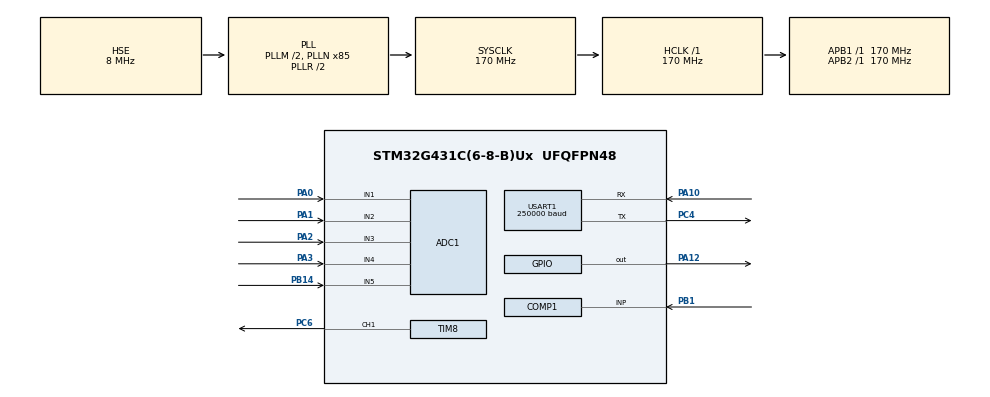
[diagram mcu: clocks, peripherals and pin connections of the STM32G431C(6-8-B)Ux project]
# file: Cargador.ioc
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ADC1.Channel-0\#ChannelRegularConversion=ADC_CHANNEL_1
ADC1.Channel-1\#ChannelRegularConversion=ADC_CHANNEL_3
ADC1.Channel-2\#ChannelRegularConversion=ADC_CHANNEL_5
ADC1.ClockPrescaler=ADC_CLOCK_ASYNC_DIV6
ADC1.DMAContinuousRequests=ENABLE
ADC1.ExternalTrigConv=ADC_EXTERNALTRIG_T6_TRGO
ADC1.ExternalTrigConvEdge=ADC_EXTERNALTRIGCONVEDGE_RISING
ADC1.NbrOfConversion=3
ADC1.NbrOfConversionFlag=1
ADC1.OffsetNumber-0\#ChannelRegularConversion=ADC_OFFSET_NONE
ADC1.OffsetNumber-1\#ChannelRegularConversion=ADC_OFFSET_NONE
ADC1.OffsetNumber-2\#ChannelRegularConversion=ADC_OFFSET_NONE
ADC1.Rank-0\#ChannelRegularConversion=1
ADC1.Rank-1\#ChannelRegularConversion=2
ADC1.Rank-2\#ChannelRegularConversion=3
ADC1.SamplingTime-0\#ChannelRegularConversion=ADC_SAMPLETIME_47CYCLES_5
ADC1.SamplingTime-1\#ChannelRegularConversion=ADC_SAMPLETIME_47CYCLES_5
ADC1.SamplingTime-2\#ChannelRegularConversion=ADC_SAMPLETIME_24CYCLES_5
ADC1.SingleDiff-0\#ChannelRegularConversion=ADC_DIFFERENTIAL_ENDED
ADC1.SingleDiff-1\#ChannelRegularConversion=ADC_DIFFERENTIAL_ENDED
ADC1.master=1
CRC.DefaultPolynomialUse=DEFAULT_POLYNOMIAL_ENABLE
CRC.InputDataFormat=CRC_INPUTDATA_FORMAT_BYTES
Dma.ADC1.0.Direction=DMA_PERIPH_TO_MEMORY
Dma.ADC1.0.EventEnable=DISABLE
Dma.ADC1.0.Instance=DMA1_Channel1
Dma.ADC1.0.MemDataAlignment=DMA_MDATAALIGN_WORD
Dma.ADC1.0.MemInc=DMA_MINC_ENABLE
Dma.ADC1.0.Mode=DMA_CIRCULAR
Dma.ADC1.0.PeriphDataAlignment=DMA_PDATAALIGN_WORD
Dma.ADC1.0.PeriphInc=DMA_PINC_DISABLE
Dma.ADC1.0.Polarity=HAL_DMAMUX_REQ_GEN_RISING
Dma.ADC1.0.Priority=DMA_PRIORITY_VERY_HIGH
Dma.ADC1.0.RequestNumber=1
Dma.ADC1.0.SignalID=NONE
Dma.ADC1.0.SyncEnable=DISABLE
Dma.ADC1.0.SyncPolarity=HAL_DMAMUX_SYNC_NO_EVENT
Dma.ADC1.0.SyncRequestNumber=1
Dma.ADC1.0.SyncSignalID=NONE
Dma.Request0=ADC1
Mcu.Family=STM32G4
Mcu.Name=STM32G431C(6-8-B)Ux
Mcu.Package=UFQFPN48
NVIC.PriorityGroup=NVIC_PRIORITYGROUP_4
NVIC.TIM2_IRQn=true\:15\:0\:false\:false\:true\:false\:true\:true
NVIC.TIM6_DAC_IRQn=true\:0\:0\:true\:false\:true\:true\:true\:true
NVIC.TIM7_IRQn=true\:4\:0\:true\:false\:true\:true\:true\:true
NVIC.TIM8_BRK_IRQn=true\:1\:0\:true\:false\:true\:true\:true\:true
NVIC.TimeBase=TIM2_IRQn
NVIC.TimeBaseIP=TIM2
PA0.Mode=IN1-Differential
PA0.Signal=ADC1_IN1
PA1.Mode=IN1-Differential
PA1.Signal=ADC1_IN2
PA10.Mode=Asynchronous
PA10.Signal=USART1_RX
PA12.PinState=GPIO_PIN_SET
PA12.Signal=GPIO_Output
PA13.Mode=Trace_Asynchronous_SW
PA13.Signal=SYS_JTMS-SWDIO
PA14.Mode=Trace_Asynchronous_SW
PA14.Signal=SYS_JTCK-SWCLK
PA2.Mode=IN3-Differential
PA2.Signal=ADC1_IN3
PA3.Mode=IN3-Differential
PA3.Signal=ADC1_IN4
PB1.Mode=INP
PB1.Signal=COMP1_INP
PB14.Mode=IN5-Single-Ended
PB14.Signal=ADC1_IN5
PB3.Mode=Trace_Asynchronous_SW
PB3.Signal=SYS_JTDO-SWO
PC4.Mode=Asynchronous
PC4.Signal=USART1_TX
PC6.Signal=S_TIM8_CH1
PF0-OSC_IN.Mode=HSE-External-Oscillator
PF0-OSC_IN.Signal=RCC_OSC_IN
PF1-OSC_OUT.Mode=HSE-External-Oscillator
PF1-OSC_OUT.Signal=RCC_OSC_OUT
ProjectManager.HeapSize=0x200
ProjectManager.StackSize=0x400
ProjectManager.TargetToolchain=STM32CubeIDE
RCC.ADC12Freq_Value=170000000
RCC.AHBFreq_Value=170000000
RCC.APB1Freq_Value=170000000
RCC.APB1TimFreq_Value=170000000
RCC.APB2Freq_Value=170000000
RCC.APB2TimFreq_Value=170000000
RCC.CortexFreq_Value=170000000
RCC.EXTERNAL_CLOCK_VALUE=12288000
RCC.HCLKFreq_Value=170000000
RCC.HSE_VALUE=8000000
RCC.HSI48_VALUE=48000000
RCC.HSI_VALUE=16000000
RCC.LSE_VALUE=32768
RCC.PLLM=RCC_PLLM_DIV2
RCC.PLLN=85
RCC.PLLSourceVirtual=RCC_PLLSOURCE_HSE
RCC.SYSCLKFreq_VALUE=170000000
RCC.SYSCLKSource=RCC_SYSCLKSOURCE_PLLCLK
RCC.USBFreq_Value=170000000
RCC.VCOOutputFreq_Value=340000000
SH.S_TIM8_CH1.0=TIM8_CH1,PWM Generation1 CH1
STMicroelectronics.X-CUBE-ALGOBUILD.1.4.0.LibraryCcDSPOoLibraryJjDSPOoLibrary=true
TIM6.AutoReloadPreload=TIM_AUTORELOAD_PRELOAD_ENABLE
TIM6.PeriodNoDither=8500
TIM6.TIM_MasterOutputTrigger=TIM_TRGO_UPDATE
TIM7.PeriodNoDither=17000
TIM7.Prescaler=9
TIM8.AutoReloadPreload=TIM_AUTORELOAD_PRELOAD_DISABLE
TIM8.BreakFilter=5
TIM8.BreakPolarity=TIM_BREAKPOLARITY_LOW
TIM8.BreakState=TIM_BREAK_ENABLE
TIM8.Channel-PWM\ Generation1\ CH1=TIM_CHANNEL_1
TIM8.OCFastMode_PWM-PWM\ Generation1\ CH1=TIM_OCFAST_ENABLE
TIM8.OffStateIDLEMode=TIM_OSSI_ENABLE
TIM8.OffStateRunMode=TIM_OSSR_ENABLE
TIM8.PeriodNoDither=11333
TIM8.PulseNoDither_1=8000
TIM8.SourceBRKCOMP1=TIM_BREAKINPUTSOURCE_ENABLE
TIM8.SourceBRKCOMP1Polarity=TIM_BREAKINPUTSOURCE_POLARITY_LOW
TIM8.TIM_MasterOutputTrigger=TIM_TRGO_UPDATE
USART1.BaudRate=250000
USART1.VirtualMode-Asynchronous=VM_ASYNC
VP_COMP1_VS_DAC1OUT1.Mode=INM_DAC1OUT1
VP_CORDIC_VS_CORDIC.Mode=CORDIC_Activate
VP_CRC_VS_CRC.Mode=CRC_Activate
VP_DAC1_VS_DACI1.Mode=DAC_OUT1_Int
VP_STMicroelectronics.X-CUBE-ALGOBUILD_VS_DSPOoLibraryJjLibrary_1.4.0_1.4.0.Mode=DSPOoLibraryJjLibrary
VP_SYS_VS_DBSignals.Mode=DisableDeadBatterySignals
VP_SYS_VS_tim2.Mode=TIM2
VP_TIM6_VS_ClockSourceINT.Mode=Enable_Timer
VP_TIM7_VS_ClockSourceINT.Mode=Enable_Timer
VP_TIM8_VS_ClockSourceINT.Mode=Internal
board=custom

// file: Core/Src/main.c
/* USER CODE BEGIN Header */
/**
 ******************************************************************************
 * @file           : main.c
 * @brief          : Main program body
 ******************************************************************************
 * @attention
 *
 * Copyright (c) 2025 STMicroelectronics.
 * All rights reserved.
 *
 * This software is licensed under terms that can be found in the LICENSE file
 * in the root directory of this software component.
 * If no LICENSE file comes with this software, it is provided AS-IS.
 *
 ******************************************************************************
 */
/* USER CODE END Header */
#include "main.h"

/* USER CODE BEGIN Includes */
#include "UserMain.h"
/* USER CODE END Includes */

ADC_HandleTypeDef hadc1;
DMA_HandleTypeDef hdma_adc1;

COMP_HandleTypeDef hcomp1;

CORDIC_HandleTypeDef hcordic;

CRC_HandleTypeDef hcrc;

DAC_HandleTypeDef hdac1;

TIM_HandleTypeDef htim6;
TIM_HandleTypeDef htim7;
TIM_HandleTypeDef htim8;

UART_HandleTypeDef huart1;

void SystemClock_Config(void);
static void MX_GPIO_Init(void);
static void MX_DMA_Init(void);
static void MX_ADC1_Init(void);
static void MX_TIM6_Init(void);
static void MX_CORDIC_Init(void);
static void MX_USART1_UART_Init(void);
static void MX_TIM7_Init(void);
static void MX_CRC_Init(void);
static void MX_TIM8_Init(void);
static void MX_DAC1_Init(void);
static void MX_COMP1_Init(void);

int main(void)
{

  /* MCU Configuration--------------------------------------------------------*/

  /* Reset of all peripherals, Initializes the Flash interface and the Systick. */
  HAL_Init();

  /* Configure the system clock */
  SystemClock_Config();

  /* Initialize all configured peripherals */
  MX_GPIO_Init();
  MX_DMA_Init();
  MX_ADC1_Init();
  MX_TIM6_Init();
  MX_CORDIC_Init();
  MX_USART1_UART_Init();
  MX_TIM7_Init();
  MX_CRC_Init();
  MX_TIM8_Init();
  MX_DAC1_Init();
  MX_COMP1_Init();
  /* USER CODE BEGIN 2 */
	setup();

  /* USER CODE END 2 */

  /* Infinite loop */
	while (1) {

    /* USER CODE BEGIN 3 */
		loop();
	}
  /* USER CODE END 3 */
}

void SystemClock_Config(void)
{
  RCC_OscInitTypeDef RCC_OscInitStruct = {0};
  RCC_ClkInitTypeDef RCC_ClkInitStruct = {0};

  /** Configure the main internal regulator output voltage
  */
  HAL_PWREx_ControlVoltageScaling(PWR_REGULATOR_VOLTAGE_SCALE1_BOOST);

  /** Initializes the RCC Oscillators according to the specified parameters
  * in the RCC_OscInitTypeDef structure.
  */
  RCC_OscInitStruct.OscillatorType = RCC_OSCILLATORTYPE_HSE;
  RCC_OscInitStruct.HSEState = RCC_HSE_ON;
  RCC_OscInitStruct.PLL.PLLState = RCC_PLL_ON;
  RCC_OscInitStruct.PLL.PLLSource = RCC_PLLSOURCE_HSE;
  RCC_OscInitStruct.PLL.PLLM = RCC_PLLM_DIV2;
  RCC_OscInitStruct.PLL.PLLN = 85;
  RCC_OscInitStruct.PLL.PLLP = RCC_PLLP_DIV2;
  RCC_OscInitStruct.PLL.PLLQ = RCC_PLLQ_DIV2;
  RCC_OscInitStruct.PLL.PLLR = RCC_PLLR_DIV2;
  if (HAL_RCC_OscConfig(&RCC_OscInitStruct) != HAL_OK)
  {
    Error_Handler();
  }

  /** Initializes the CPU, AHB and APB buses clocks
  */
  RCC_ClkInitStruct.ClockType = RCC_CLOCKTYPE_HCLK|RCC_CLOCKTYPE_SYSCLK
                              |RCC_CLOCKTYPE_PCLK1|RCC_CLOCKTYPE_PCLK2;
  RCC_ClkInitStruct.SYSCLKSource = RCC_SYSCLKSOURCE_PLLCLK;
  RCC_ClkInitStruct.AHBCLKDivider = RCC_SYSCLK_DIV1;
  RCC_ClkInitStruct.APB1CLKDivider = RCC_HCLK_DIV1;
  RCC_ClkInitStruct.APB2CLKDivider = RCC_HCLK_DIV1;

  if (HAL_RCC_ClockConfig(&RCC_ClkInitStruct, FLASH_LATENCY_4) != HAL_OK)
  {
    Error_Handler();
  }
}

static void MX_ADC1_Init(void)
{

  ADC_MultiModeTypeDef multimode = {0};
  ADC_ChannelConfTypeDef sConfig = {0};

  /** Common config
  */
  hadc1.Instance = ADC1;
  hadc1.Init.ClockPrescaler = ADC_CLOCK_ASYNC_DIV6;
  hadc1.Init.Resolution = ADC_RESOLUTION_12B;
  hadc1.Init.DataAlign = ADC_DATAALIGN_RIGHT;
  hadc1.Init.GainCompensation = 0;
  hadc1.Init.ScanConvMode = ADC_SCAN_ENABLE;
  hadc1.Init.EOCSelection = ADC_EOC_SINGLE_CONV;
  hadc1.Init.LowPowerAutoWait = DISABLE;
  hadc1.Init.ContinuousConvMode = DISABLE;
  hadc1.Init.NbrOfConversion = 3;
  hadc1.Init.DiscontinuousConvMode = DISABLE;
  hadc1.Init.ExternalTrigConv = ADC_EXTERNALTRIG_T6_TRGO;
  hadc1.Init.ExternalTrigConvEdge = ADC_EXTERNALTRIGCONVEDGE_RISING;
  hadc1.Init.DMAContinuousRequests = ENABLE;
  hadc1.Init.Overrun = ADC_OVR_DATA_PRESERVED;
  hadc1.Init.OversamplingMode = DISABLE;
  if (HAL_ADC_Init(&hadc1) != HAL_OK)
  {
    Error_Handler();
  }

  /** Configure the ADC multi-mode
  */
  multimode.Mode = ADC_MODE_INDEPENDENT;
  if (HAL_ADCEx_MultiModeConfigChannel(&hadc1, &multimode) != HAL_OK)
  {
    Error_Handler();
  }

  /** Configure Regular Channel
  */
  sConfig.Channel = ADC_CHANNEL_1;
  sConfig.Rank = ADC_REGULAR_RANK_1;
  sConfig.SamplingTime = ADC_SAMPLETIME_47CYCLES_5;
  sConfig.SingleDiff = ADC_DIFFERENTIAL_ENDED;
  sConfig.OffsetNumber = ADC_OFFSET_NONE;
  sConfig.Offset = 0;
  if (HAL_ADC_ConfigChannel(&hadc1, &sConfig) != HAL_OK)
  {
    Error_Handler();
  }

  /** Configure Regular Channel
  */
  sConfig.Channel = ADC_CHANNEL_3;
  sConfig.Rank = ADC_REGULAR_RANK_2;
  if (HAL_ADC_ConfigChannel(&hadc1, &sConfig) != HAL_OK)
  {
    Error_Handler();
  }

  /** Configure Regular Channel
  */
  sConfig.Channel = ADC_CHANNEL_5;
  sConfig.Rank = ADC_REGULAR_RANK_3;
  sConfig.SamplingTime = ADC_SAMPLETIME_24CYCLES_5;
  sConfig.SingleDiff = ADC_SINGLE_ENDED;
  if (HAL_ADC_ConfigChannel(&hadc1, &sConfig) != HAL_OK)
  {
    Error_Handler();
  }

}

static void MX_COMP1_Init(void)
{

  hcomp1.Instance = COMP1;
  hcomp1.Init.InputPlus = COMP_INPUT_PLUS_IO2;
  hcomp1.Init.InputMinus = COMP_INPUT_MINUS_DAC1_CH1;
  hcomp1.Init.OutputPol = COMP_OUTPUTPOL_NONINVERTED;
  hcomp1.Init.Hysteresis = COMP_HYSTERESIS_NONE;
  hcomp1.Init.BlankingSrce = COMP_BLANKINGSRC_NONE;
  hcomp1.Init.TriggerMode = COMP_TRIGGERMODE_NONE;
  if (HAL_COMP_Init(&hcomp1) != HAL_OK)
  {
    Error_Handler();
  }

}

static void MX_CORDIC_Init(void)
{

  hcordic.Instance = CORDIC;
  if (HAL_CORDIC_Init(&hcordic) != HAL_OK)
  {
    Error_Handler();
  }

}

static void MX_CRC_Init(void)
{

  hcrc.Instance = CRC;
  hcrc.Init.DefaultPolynomialUse = DEFAULT_POLYNOMIAL_ENABLE;
  hcrc.Init.DefaultInitValueUse = DEFAULT_INIT_VALUE_ENABLE;
  hcrc.Init.InputDataInversionMode = CRC_INPUTDATA_INVERSION_NONE;
  hcrc.Init.OutputDataInversionMode = CRC_OUTPUTDATA_INVERSION_DISABLE;
  hcrc.InputDataFormat = CRC_INPUTDATA_FORMAT_BYTES;
  if (HAL_CRC_Init(&hcrc) != HAL_OK)
  {
    Error_Handler();
  }

}

static void MX_DAC1_Init(void)
{

  DAC_ChannelConfTypeDef sConfig = {0};

  /** DAC Initialization
  */
  hdac1.Instance = DAC1;
  if (HAL_DAC_Init(&hdac1) != HAL_OK)
  {
    Error_Handler();
  }

  /** DAC channel OUT1 config
  */
  sConfig.DAC_HighFrequency = DAC_HIGH_FREQUENCY_INTERFACE_MODE_AUTOMATIC;
  sConfig.DAC_DMADoubleDataMode = DISABLE;
  sConfig.DAC_SignedFormat = DISABLE;
  sConfig.DAC_SampleAndHold = DAC_SAMPLEANDHOLD_DISABLE;
  sConfig.DAC_Trigger = DAC_TRIGGER_NONE;
  sConfig.DAC_Trigger2 = DAC_TRIGGER_NONE;
  sConfig.DAC_OutputBuffer = DAC_OUTPUTBUFFER_DISABLE;
  sConfig.DAC_ConnectOnChipPeripheral = DAC_CHIPCONNECT_INTERNAL;
  sConfig.DAC_UserTrimming = DAC_TRIMMING_FACTORY;
  if (HAL_DAC_ConfigChannel(&hdac1, &sConfig, DAC_CHANNEL_1) != HAL_OK)
  {
    Error_Handler();
  }

}

static void MX_TIM6_Init(void)
{

  TIM_MasterConfigTypeDef sMasterConfig = {0};

  htim6.Instance = TIM6;
  htim6.Init.Prescaler = 0;
  htim6.Init.CounterMode = TIM_COUNTERMODE_UP;
  htim6.Init.Period = 8500;
  htim6.Init.AutoReloadPreload = TIM_AUTORELOAD_PRELOAD_ENABLE;
  if (HAL_TIM_Base_Init(&htim6) != HAL_OK)
  {
    Error_Handler();
  }
  sMasterConfig.MasterOutputTrigger = TIM_TRGO_UPDATE;
  sMasterConfig.MasterSlaveMode = TIM_MASTERSLAVEMODE_DISABLE;
  if (HAL_TIMEx_MasterConfigSynchronization(&htim6, &sMasterConfig) != HAL_OK)
  {
    Error_Handler();
  }

}

static void MX_TIM7_Init(void)
{

  TIM_MasterConfigTypeDef sMasterConfig = {0};

  htim7.Instance = TIM7;
  htim7.Init.Prescaler = 9;
  htim7.Init.CounterMode = TIM_COUNTERMODE_UP;
  htim7.Init.Period = 17000;
  htim7.Init.AutoReloadPreload = TIM_AUTORELOAD_PRELOAD_DISABLE;
  if (HAL_TIM_Base_Init(&htim7) != HAL_OK)
  {
    Error_Handler();
  }
  sMasterConfig.MasterOutputTrigger = TIM_TRGO_RESET;
  sMasterConfig.MasterSlaveMode = TIM_MASTERSLAVEMODE_DISABLE;
  if (HAL_TIMEx_MasterConfigSynchronization(&htim7, &sMasterConfig) != HAL_OK)
  {
    Error_Handler();
  }

}

static void MX_TIM8_Init(void)
{

  TIM_ClockConfigTypeDef sClockSourceConfig = {0};
  TIM_MasterConfigTypeDef sMasterConfig = {0};
  TIMEx_BreakInputConfigTypeDef sBreakInputConfig = {0};
  TIM_OC_InitTypeDef sConfigOC = {0};
  TIM_BreakDeadTimeConfigTypeDef sBreakDeadTimeConfig = {0};

  htim8.Instance = TIM8;
  htim8.Init.Prescaler = 0;
  htim8.Init.CounterMode = TIM_COUNTERMODE_UP;
  htim8.Init.Period = 11333;
  htim8.Init.ClockDivision = TIM_CLOCKDIVISION_DIV1;
  htim8.Init.RepetitionCounter = 0;
  htim8.Init.AutoReloadPreload = TIM_AUTORELOAD_PRELOAD_DISABLE;
  if (HAL_TIM_Base_Init(&htim8) != HAL_OK)
  {
    Error_Handler();
  }
  sClockSourceConfig.ClockSource = TIM_CLOCKSOURCE_INTERNAL;
  if (HAL_TIM_ConfigClockSource(&htim8, &sClockSourceConfig) != HAL_OK)
  {
    Error_Handler();
  }
  if (HAL_TIM_PWM_Init(&htim8) != HAL_OK)
  {
    Error_Handler();
  }
  sMasterConfig.MasterOutputTrigger = TIM_TRGO_UPDATE;
  sMasterConfig.MasterOutputTrigger2 = TIM_TRGO2_RESET;
  sMasterConfig.MasterSlaveMode = TIM_MASTERSLAVEMODE_DISABLE;
  if (HAL_TIMEx_MasterConfigSynchronization(&htim8, &sMasterConfig) != HAL_OK)
  {
    Error_Handler();
  }
  sBreakInputConfig.Source = TIM_BREAKINPUTSOURCE_COMP1;
  sBreakInputConfig.Enable = TIM_BREAKINPUTSOURCE_ENABLE;
  sBreakInputConfig.Polarity = TIM_BREAKINPUTSOURCE_POLARITY_LOW;
  if (HAL_TIMEx_ConfigBreakInput(&htim8, TIM_BREAKINPUT_BRK, &sBreakInputConfig) != HAL_OK)
  {
    Error_Handler();
  }
  sConfigOC.OCMode = TIM_OCMODE_PWM1;
  sConfigOC.Pulse = 8000;
  sConfigOC.OCPolarity = TIM_OCPOLARITY_HIGH;
  sConfigOC.OCNPolarity = TIM_OCNPOLARITY_HIGH;
  sConfigOC.OCFastMode = TIM_OCFAST_ENABLE;
  sConfigOC.OCIdleState = TIM_OCIDLESTATE_RESET;
  sConfigOC.OCNIdleState = TIM_OCNIDLESTATE_RESET;
  if (HAL_TIM_PWM_ConfigChannel(&htim8, &sConfigOC, TIM_CHANNEL_1) != HAL_OK)
  {
    Error_Handler();
  }
  sBreakDeadTimeConfig.OffStateRunMode = TIM_OSSR_ENABLE;
  sBreakDeadTimeConfig.OffStateIDLEMode = TIM_OSSI_ENABLE;
  sBreakDeadTimeConfig.LockLevel = TIM_LOCKLEVEL_OFF;
  sBreakDeadTimeConfig.DeadTime = 0;
  sBreakDeadTimeConfig.BreakState = TIM_BREAK_ENABLE;
  sBreakDeadTimeConfig.BreakPolarity = TIM_BREAKPOLARITY_LOW;
  sBreakDeadTimeConfig.BreakFilter = 5;
  sBreakDeadTimeConfig.BreakAFMode = TIM_BREAK_AFMODE_INPUT;
  sBreakDeadTimeConfig.Break2State = TIM_BREAK2_DISABLE;
  sBreakDeadTimeConfig.Break2Polarity = TIM_BREAK2POLARITY_HIGH;
  sBreakDeadTimeConfig.Break2Filter = 0;
  sBreakDeadTimeConfig.Break2AFMode = TIM_BREAK_AFMODE_INPUT;
  sBreakDeadTimeConfig.AutomaticOutput = TIM_AUTOMATICOUTPUT_DISABLE;
  if (HAL_TIMEx_ConfigBreakDeadTime(&htim8, &sBreakDeadTimeConfig) != HAL_OK)
  {
    Error_Handler();
  }
  HAL_TIM_MspPostInit(&htim8);

}

static void MX_USART1_UART_Init(void)
{

  huart1.Instance = USART1;
  huart1.Init.BaudRate = 250000;
  huart1.Init.WordLength = UART_WORDLENGTH_8B;
  huart1.Init.StopBits = UART_STOPBITS_1;
  huart1.Init.Parity = UART_PARITY_NONE;
  huart1.Init.Mode = UART_MODE_TX_RX;
  huart1.Init.HwFlowCtl = UART_HWCONTROL_NONE;
  huart1.Init.OverSampling = UART_OVERSAMPLING_16;
  huart1.Init.OneBitSampling = UART_ONE_BIT_SAMPLE_DISABLE;
  huart1.Init.ClockPrescaler = UART_PRESCALER_DIV1;
  huart1.AdvancedInit.AdvFeatureInit = UART_ADVFEATURE_NO_INIT;
  if (HAL_UART_Init(&huart1) != HAL_OK)
  {
    Error_Handler();
  }
  if (HAL_UARTEx_SetTxFifoThreshold(&huart1, UART_TXFIFO_THRESHOLD_1_8) != HAL_OK)
  {
    Error_Handler();
  }
  if (HAL_UARTEx_SetRxFifoThreshold(&huart1, UART_RXFIFO_THRESHOLD_1_8) != HAL_OK)
  {
    Error_Handler();
  }
  if (HAL_UARTEx_DisableFifoMode(&huart1) != HAL_OK)
  {
    Error_Handler();
  }

}

static void MX_DMA_Init(void)
{

  /* DMA controller clock enable */
  __HAL_RCC_DMAMUX1_CLK_ENABLE();
  __HAL_RCC_DMA1_CLK_ENABLE();

}

static void MX_GPIO_Init(void)
{
  GPIO_InitTypeDef GPIO_InitStruct = {0};

  /* GPIO Ports Clock Enable */
  __HAL_RCC_GPIOF_CLK_ENABLE();
  __HAL_RCC_GPIOA_CLK_ENABLE();
  __HAL_RCC_GPIOC_CLK_ENABLE();
  __HAL_RCC_GPIOB_CLK_ENABLE();

  /*Configure GPIO pin Output Level */
  HAL_GPIO_WritePin(GPIOA, GPIO_PIN_12, GPIO_PIN_SET);

  /*Configure GPIO pin : PA12 */
  GPIO_InitStruct.Pin = GPIO_PIN_12;
  GPIO_InitStruct.Mode = GPIO_MODE_OUTPUT_PP;
  GPIO_InitStruct.Pull = GPIO_NOPULL;
  GPIO_InitStruct.Speed = GPIO_SPEED_FREQ_LOW;
  HAL_GPIO_Init(GPIOA, &GPIO_InitStruct);

}

void HAL_TIM_PeriodElapsedCallback(TIM_HandleTypeDef *htim)
{
  if (htim->Instance == TIM2)
  {
    HAL_IncTick();
  }
}

void Error_Handler(void)
{
	__disable_irq();
	while (1) {
	}
}
